# NUC1263AE register map
File version: 1.0
Registers are 32-bit, read-write, reset 0x0 unless marked. A register's access mark holds for its fields unless they carry their own. Offsets are from the block's base; [hi:lo] are bit positions; {n}, {i} and the like mark numbered series; 'fields as' and 'values as' point back to an identical list.

## USBD — USBD Register Map
Base 0x40060000
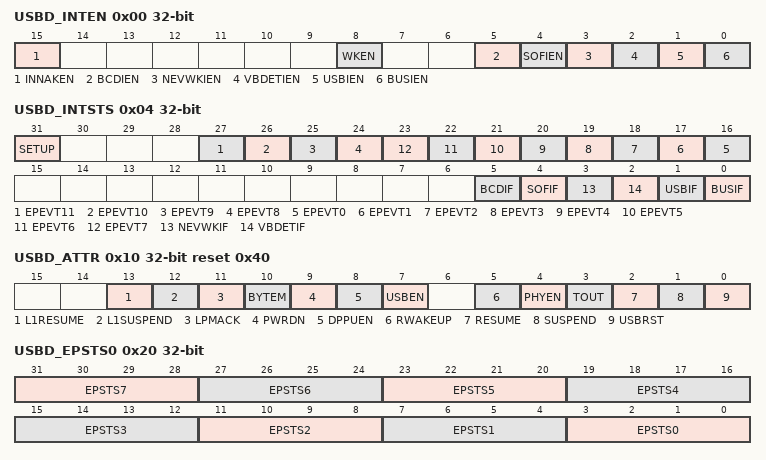
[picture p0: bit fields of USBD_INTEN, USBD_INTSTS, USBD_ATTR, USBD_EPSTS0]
0x00 USBD_INTEN — USB Device Interrupt Enable Register
  [15] INNAKEN — Active NAK Function and Its Status in IN Token
    0=When the device responds NAK after receiving IN token, IN NAK status will not be updated to USBD_EPSTS0 and USBD_EPSTS1 register, so that the USB interrupt event will not be asserted; 1=IN NAK status will be updated to USBD_EPSTS0 and USBD_EPSTS1 register and the USB interrupt event will be asserted when the device responds NAK after receiving IN token
  [8] WKEN — Wake-up Function Enable Bit. Note: If woken up by any change by VBUS state, VBDETIEN must be enabled. If woken up by receiving resume signal, BUSIEN must be enabled.
    0=USB wake-up function Disabled; 1=USB wake-up function Enabled
  [5] BCDIEN — Battery Charge Detect Interrupt Enable Bit
    0=BCD Interrupt Disabled; 1=BCD Interrupt Enabled
  [4] SOFIEN — Start of Frame Interrupt Enable Bit
    0=SOF Interrupt Disabled; 1=SOF Interrupt Enabled
  [3] NEVWKIEN — USB No-event-wake-up Interrupt Enable Bit
    0=No-event-wake-up Interrupt Disabled; 1=No-event-wake-up Interrupt Enabled
  [2] VBDETIEN — VBUS Detection Interrupt Enable Bit
    0=VBUS detection Interrupt Disabled; 1=VBUS detection Interrupt Enabled
  [1] USBIEN — USB Event Interrupt Enable Bit
    0=USB event interrupt Disabled; 1=USB event interrupt Enabled
  [0] BUSIEN — Bus Event Interrupt Enable Bit
    0=BUS event interrupt Disabled; 1=BUS event interrupt Enabled
0x04 USBD_INTSTS — USB Device Interrupt Event Status Register
  [31] SETUP — Setup Event Status
    0=No Setup event; 1=Setup event occurred, and it is cleared by writing 1 to USBD_INTSTS[31]
  [27] EPEVT11 — Endpoint 11's USB Event Status
    0=No event occurred in endpoint 11; 1=USB event occurred on Endpoint 11; check USBD_EPSTS1[15:12] to know which kind of USB event occurred, and it is cleared by writing 1 to USBD_INTSTS[27] or USBD_INTSTS[1]
  [26] EPEVT10 — Endpoint 10's USB Event Status
    0=No event occurred in endpoint 10; 1=USB event occurred on Endpoint 10, check USBD_EPSTS1[11:8] to know which kind of USB event occurred, and it is cleared by writing 1 to USBD_INTSTS[26] or USBD_INTSTS[1]
  [25] EPEVT9 — Endpoint 9's USB Event Status
    0=No event occurred in endpoint 9; 1=USB event occurred on Endpoint 9, check USBD_EPSTS1[7:4] to know which kind of USB event occurred, and it is cleared by writing 1 to USBD_INTSTS[25] or USBD_INTSTS[1]
  [24] EPEVT8 — Endpoint 8's USB Event Status
    0=No event occurred in endpoint 8; 1=USB event occurred on Endpoint 8; check USBD_EPSTS1[3:0] to know which kind of USB event occurred, and it is cleared by writing 1 to USBD_INTSTS[24] or USBD_INTSTS[1]
  [n+16] EPEVT{n} (n=0..7) — Endpoint {n}'s USB Event Status
    0=No event occurred in endpoint {n}; 1=USB event occurred on Endpoint {n}, check USBD_EPSTS0[{4n+3}:{4n}] to know which kind of USB event occurred, and it is cleared by writing 1 to USBD_INTSTS[{n+16}] or USBD_INTSTS[1]
  [5] BCDIF — Battery Charge Detect Interrupt Status. It supports VBUSOK and DCD interrupt status
    0=BCD event did not occur; 1=BCD event occurred, and it is cleared by writing 1 to USBD_INTSTS[5]
  [4] SOFIF — Start of Frame Interrupt Status
    0=SOF event did not occur; 1=SOF event occurred, and it is cleared by writing 1 to USBD_INTSTS[4]
  [3] NEVWKIF — No-event-wake-up Interrupt Status
    0=NEVWK event did not occur; 1=No-event-wake-up event occurred, and it is cleared by writing 1 to USBD_INTSTS[3]
  [2] VBDETIF — VBUS Detection Interrupt Status
    0=There is not attached/detached event in the USB; 1=There is attached/detached event in the USB bus and it is cleared by writing 1 to USBD_INTSTS[2]
  [1] USBIF — USB Event Interrupt Status. The USB event includes the SETUP Token, IN Token, OUT ACK, ISO IN, or ISO OUT events in the bus.
    0=No USB event occurred; 1=USB event occurred; check EPSTS0~11[3:0] to know which kind of USB event occurred, and it is cleared by writing 1 to USBD_INTSTS[1] or EPSTS0~11 and SETUP (USBD_INTSTS[31])
  [0] BUSIF — BUS Interrupt Status. The BUS event means that there is one of the suspend or the resume function in the bus.
    0=No BUS event occurred; 1=Bus event occurred; check USBD_ATTR[3:0] to know which kind of bus event occurred, and it is cleared by writing 1 to USBD_INTSTS[0]
0x08 USBD_FADDR — USB Device Function Address Register
  [6:0] FADDR — USB Device Function Address
0x0C USBD_EPSTS ro — USB Device Endpoint Status Register
  [7] OV — Overrun. It indicates that the received data is over the maximum payload number or not.
    0=No overrun; 1=Out Data is more than the Max Payload in MXPLD register or the Setup Data is more than 8 Bytes
0x10 USBD_ATTR reset 0x40 — USB Device Bus Status and Attribution Register
  [13] L1RESUME ro — LPM L1 Resume (Read Only)
    0=Bus no LPM L1 state resume; 1=LPM L1 state resume from LPM L1 state suspend
  [12] L1SUSPEND ro — LPM L1 Suspend (Read Only)
    0=Bus no L1 state suspend; 1=This bit is set by the hardware when LPM command to enter the L1 state is successfully received and acknowledged
  [11] LPMACK — LPM Token Acknowledge Enable Bit
    0=The valid LPM Token will be NYET; 1=The valid LPM Token will be ACK
  [10] BYTEM — CPU Access USB SRAM Size Mode Selection
    0=Word mode: The size of the transfer from CPU to USB SRAM can be Word only; 1=Byte mode: The size of the transfer from CPU to USB SRAM can be Byte only
  [9] PWRDN — Power-down PHY Transceiver, Low Active
    0=Power-down related circuit of PHY transceiver; 1=Turn-on related circuit of PHY transceiver
  [8] DPPUEN — Pull-up Resistor on USB_DP Enable Bit
    0=Pull-up resistor in USB_D+ bus Disabled; 1=Pull-up resistor in USB_D+ bus Active
  [7] USBEN — USB Controller Enable Bit
    0=USB Controller Disabled; 1=USB Controller Enabled
  [5] RWAKEUP — Remote Wake-up
    0=Release the USB bus from K state; 1=Force USB bus to K (USB_D+ low, USB_D- high) state, used for remote wake-up
  [4] PHYEN — PHY Transceiver Function Enable Bit
    0=PHY transceiver function Disabled; 1=PHY transceiver function Enabled
  [3] TOUT ro — Time-out Status (Read Only)
    0=No time-out; 1=No Bus response more than 18 bits time (
  [2] RESUME ro — Resume Status (Read Only)
    0=No bus resume; 1=Resume from suspend
  [1] SUSPEND ro — Suspend Status (Read Only)
    0=Bus no suspend; 1=Bus idle more than 3ms, either cable is plugged out or host is sleeping
  [0] USBRST ro — USB Reset Status (Read Only)
    0=Bus no reset; 1=Bus reset when SE0 (single-ended 0) more than 2.5us
0x14 USBD_VBUSDET ro — USB Device VBUS Detection Register
  [0] VBUSDET — Device VBUS Detection
    0=Controller is not attached to the USB host; 1=Controller is attached to the USB host
0x18 USBD_STBUFSEG — SETUP Token Buffer Segmentation Register
  [8:3] STBUFSEG — SETUP Token Buffer Segmentation. It is used to indicate the offset address for the SETUP token with the USB Device SRAM starting address The effective starting address is. USBD_SRAM address + {STBUFSEG, 3'b000} Note: It is used for SETUP token only.
0x20 USBD_EPSTS0 ro — USB Device Endpoint Status Register 0
  [31:28] EPSTS7 — Endpoint 7 Status. These bits are used to indicate the current status of this endpoint
    0=In ACK; 1=In NAK; 2=Out Packet Data0 ACK; 6=Out Packet Data1 ACK; 7=Isochronous transfer end
  [27:24] EPSTS6 — Endpoint 6 Status. These bits are used to indicate the current status of this endpoint
    values as EPSTS7
  [23:20] EPSTS5 — Endpoint 5 Status. These bits are used to indicate the current status of this endpoint
    values as EPSTS7
  [19:16] EPSTS4 — Endpoint 4 Status. These bits are used to indicate the current status of this endpoint
    0=In ACK; 1=In NAK; 2=Out Packet Data0 ACK; 6=Out Packet Data1 ACK; 7=Isochronous Transfer End
  [4n+3:4n] EPSTS{n} (n=0..3) — Endpoint {n} Status. These bits are used to indicate the current status of this endpoint
    values as EPSTS7
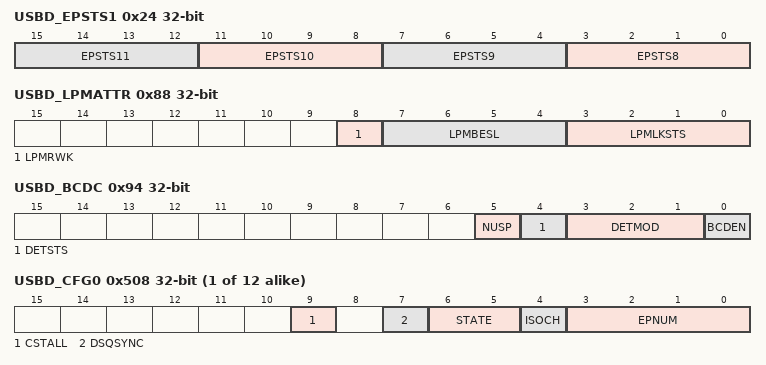
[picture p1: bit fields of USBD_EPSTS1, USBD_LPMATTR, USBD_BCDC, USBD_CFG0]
0x24 USBD_EPSTS1 ro — USB Device Endpoint Status Register 1
  [all] fields
    values as USBD_EPSTS0.EPSTS7
  [4n-29:4n-32] EPSTS{n} (n=8..11) — Endpoint {n} Status. These bits are used to indicate the current status of this endpoint
0x88 USBD_LPMATTR ro — USB LPM Attribution Register
  [8] LPMRWK — LPM Remote Wake-up. This bit contains the bRemoteWake value received with last ACK LPM Token
  [7:4] LPMBESL — LPM Best Effort Service Latency. These bits contain the BESL value received with last ACK LPM Token
  [3:0] LPMLKSTS — LPM Link State. These bits contain the bLinkState received with last ACK LPM Token
0x8C USBD_FN ro (reset mask 0xFFFFF000) — USB Frame Number Register
  [10:0] FN — Frame Number. These bits contain the 11-bits frame number in the last received SOF packet. Note: Suggest to read USBD_FN after USBD_INTSTS[4] SOFIF interrupt is triggered and cleaned.
0x90 USBD_SE0 reset 0x1 — USB Device Drive SE0 Control Register
  [0] SE0 — Drive Single Ended Zero in USB Bus. The Single Ended Zero (SE0) is when both lines (USB_D+ and USB_D-) are being pulled low.
    0=Normal operation; 1=Force USB PHY transceiver to drive SE0
0x94 USBD_BCDC — USB Device Battery Charge Detect Control Register
  [5] NUSP ro — Not USB Support Port (Read Only)
    0=USB support port; 1=Not USB support port
  [4] DETSTS ro — Detect Status (Read Only)
    0=VBUS is less than threshold voltage. Data pin not contacted. SDP port or not USB support port. If it is not USB support port, NUSP is 1. CDP; 1=VBUS is greater than threshold voltage. Data pin contacted. DCP or CDP. DCP
  [3:1] DETMOD — Detect Mode
    0=Idle, nothing to detect; 1=VBUS detect, detect USB VBUS whether great than threshold voltage; 2=Data contact detect (DCD), detect data pin contact status; 3=Primary detect (PD), distinguish between (SDP or NUSP) and (CDP or DCP); 4=Secondary detect (SD), distinguish between CDP and DCP
  [0] BCDEN — Battery Charge Detect Enable Bit. Enable battery charge detect, select DETMOD and then observer DETSTS to decide contact port.
    0=Normal operation; 1=Battery charge detect operation
{0x500+0x10*i} USBD_BUFSEG{i} (i=0..11) — Endpoint {i} Buffer Segmentation Register
  [8:3] BUFSEG — Endpoint Buffer Segmentation. It is used to indicate the offset address for each endpoint with the USB SRAM starting address. The effective starting address of the endpoint is: USBD_SRAM address + { BUFSEG, 3'b000} Refer to the section 6.15.5.7 for the endpoint SRAM structure and its description.
{0x504+0x10*i} USBD_MXPLD{i} (i=0..11) — Endpoint {i} Maximal Payload Register
  [8:0] MXPLD — Maximal Payload. Define the data length which is transmitted to host (IN token) or the actual data length which is received from the host (OUT token). It also used to indicate that the endpoint is ready to be transmitted in IN token or received in OUT token. (1) When the register is written by CPU, For IN token, the value of MXPLD is used to define the data length to be transmitted and indicate the data buffer is ready. For OUT token, it means that the controller is ready to receive data from the host and the value of MXPLD is the maximal data length comes from host. (2) When the register is read by CPU, For IN token, the value of MXPLD is indicated by the data length be transmitted to host. For OUT token, the value of MXPLD is indicated the actual data length receiving from host. Note: Once MXPLD is written, the data packets will be transmitted/received immediately after IN/OUT token arrived.
{0x508+0x10*i} USBD_CFG{i} (i=0..11) — Endpoint {i} Configuration Register
  [9] CSTALL — Clear STALL Response
    0=Disable the device to clear the STALL handshake in setup stage; 1=Clear the device to response STALL handshake in setup stage
  [7] DSQSYNC — Data Sequence Synchronization. Note: It is used to specify the DATA0 or DATA1 PID in the following IN token transaction. Hardware will toggle automatically in IN token base on this bit.
    0=DATA0 PID; 1=DATA1 PID
  [6:5] STATE — Endpoint State
    0=Endpoint is Disabled; 1=Out endpoint; 2=IN endpoint; 3=Undefined
  [4] ISOCH — Isochronous Endpoint. This bit is used to set the endpoint as Isochronous endpoint, no handshake.
    0=No Isochronous endpoint; 1=Isochronous endpoint
  [3:0] EPNUM — Endpoint Number. These bits are used to define the endpoint number of the current endpoint.
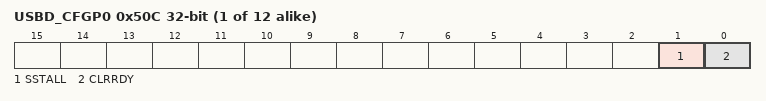
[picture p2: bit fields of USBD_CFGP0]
{0x50C+0x10*i} USBD_CFGP{i} (i=0..11) — Endpoint {i} Set Stall and Clear In/Out Ready Control Register
  [1] SSTALL — Set STALL
    0=Disable the device to response STALL; 1=Set the device to respond STALL automatically
  [0] CLRRDY — Clear Ready. When the USBD_MXPLDx register is set by user, it means that the endpoint is ready to transmit or receive data. If the user wants to disable this transaction before the transaction start, users can set this bit to 1 to disable it and it is auto clear to 0. For IN token, write '1' to clear the IN token had ready to transmit the data to USB. For OUT token, write '1' to clear the OUT token had ready to receive the data from USB. This bit is write 1 only and is always 0 when it is read back.
